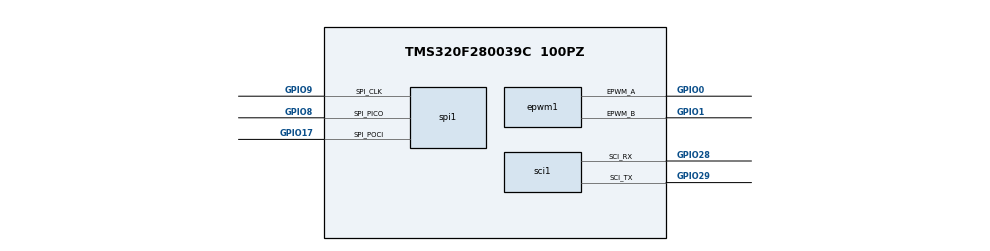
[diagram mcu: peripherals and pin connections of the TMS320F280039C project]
/**
 * These arguments were used when this file was generated. They will be automatically applied on subsequent loads
 * via the GUI or CLI. Run CLI with '--help' for additional information on how to override these arguments.
 * @cliArgs --device "F28003x" --part "F28003x_100PZ" --package "100PZ" --context "system" --product "gmp_pro@1.00.00.05" --product "gmp_pro@1.00.00.05" --product "C2000WARE@5.03.00.00"
 * @v2CliArgs --device "TMS320F280039C" --package "100PZ" --context "system" --product "gmp_pro@1.00.00.05" --product "gmp_pro@1.00.00.05" --product "C2000WARE@5.03.00.00"
 * @versions {"tool":"1.21.0+3721"}
 */

/**
 * Import the modules used in this configuration.
 */
const adc            = scripting.addModule("/driverlib/adc.js", {}, false);
const adc1           = adc.addInstance();
const device_support = scripting.addModule("/driverlib/device_support.js");
const epwm           = scripting.addModule("/driverlib/epwm.js", {}, false);
const epwm1          = epwm.addInstance();
const epwm2          = epwm.addInstance();
const epwm3          = epwm.addInstance();
const sci            = scripting.addModule("/driverlib/sci.js", {}, false);
const sci1           = sci.addInstance();
const spi            = scripting.addModule("/driverlib/spi.js", {}, false);
const spi1           = spi.addInstance();

/**
 * Write custom configuration values to the imported modules.
 */
adc1.$name                          = "myADC0";
adc1.adcClockPrescaler              = "ADC_CLK_DIV_2_0";
adc1.enabledInts                    = ["ADC_INT_NUMBER1"];
adc1.enableInterrupt1ContinuousMode = true;
adc1.enableInterrupt1               = true;

const analog  = scripting.addModule("/driverlib/analog.js", {}, false);
const analog1 = analog.addInstance({}, false);
analog1.$name = "myANALOGPinMux0";
adc1.analog   = analog1;

const divider5       = system.clockTree["PLL_REFDIV"];
divider5.divideValue = 2;

const mux3       = system.clockTree["OSCCLKSRCSEL"];
mux3.inputSelect = "X1_XTAL";

epwm1.$name                                                      = "EPWMU";
epwm1.epwmTimebase_hsClockDiv                                    = "EPWM_HSCLOCK_DIVIDER_1";
epwm1.epwmTimebase_period                                        = 6000;
epwm1.epwmTimebase_counterMode                                   = "EPWM_COUNTER_MODE_UP_DOWN";
epwm1.epwmTimebase_counterModeAfterSync                          = "EPWM_COUNT_MODE_UP_AFTER_SYNC";
epwm1.epwmTimebase_phaseEnable                                   = true;
epwm1.epwmTimebase_syncOutPulseMode                              = ["EPWM_SYNC_OUT_PULSE_ON_CNTR_ZERO"];
epwm1.epwmCounterCompare_cmpA                                    = 3000;
epwm1.epwmCounterCompare_shadowLoadModeCMPA                      = "EPWM_COMP_LOAD_ON_CNTR_ZERO_PERIOD";
epwm1.epwmActionQualifier_EPWM_AQ_OUTPUT_A_ON_TIMEBASE_UP_CMPA   = "EPWM_AQ_OUTPUT_LOW";
epwm1.epwmActionQualifier_EPWM_AQ_OUTPUT_A_ON_TIMEBASE_DOWN_CMPA = "EPWM_AQ_OUTPUT_HIGH";
epwm1.epwmDeadband_delayRED                                      = 75;
epwm1.epwmDeadband_delayFED                                      = 75;
epwm1.epwmEventTrigger_enableInterrupt                           = true;
epwm1.epwmEventTrigger_EPWM_SOC_A_triggerEnable                  = true;
epwm1.epwmEventTrigger_EPWM_SOC_A_triggerSource                  = "EPWM_SOC_TBCTR_PERIOD";
epwm1.epwmEventTrigger_EPWM_SOC_A_triggerEventPrescalar          = "1";
epwm1.epwm.$assign                                               = "EPWM1";
epwm1.epwm.epwm_aPin.$assign                                     = "GPIO0";
epwm1.epwm.epwm_bPin.$assign                                     = "GPIO1";

epwm2.$name = "EPWMV";

epwm3.$name = "EPWMW";

sci1.$name                 = "debug_uart";
sci1.useInterrupts         = false;
sci1.sci.sci_rxPin.$assign = "GPIO28";
sci1.sci.sci_txPin.$assign = "GPIO29";
sci1.rxQual.$name          = "myGPIOQUAL0";
sci1.txQual.$name          = "myGPIOQUAL1";

spi1.$name                   = "Encoder_SPI";
spi1.useCase                 = "CUSTOM";
spi1.useInterfacePins        = ["SPI@_CLK","SPI@_SIMO","SPI@_SOMI"];
spi1.useInterrupts           = false;
spi1.picoQual.$name          = "myGPIOQUAL2";
spi1.pociQual.$name          = "myGPIOQUAL3";
spi1.spi.spi_picoPin.$assign = "GPIO8";
spi1.spi.spi_pociPin.$assign = "GPIO17";
spi1.spi.spi_clkPin.$assign  = "GPIO9";
spi1.clkQual.$name           = "myGPIOQUAL4";

/**
 * Pinmux solution for unlocked pins/peripherals. This ensures that minor changes to the automatic solver in a future
 * version of the tool will not impact the pinmux you originally saw.  These lines can be completely deleted in order to
 * re-solve from scratch.
 */
analog1.analog.$suggestSolution                           = "ANALOG";
analog1.analog["a0/b15/c15/daca_outPin"].$suggestSolution = "A0/B15/C15/DACA_OUT";
analog1.analog["a1/b7/dacb_outPin"].$suggestSolution      = "A1/B7/DACB_OUT";
analog1.analog["a10/b1/c10Pin"].$suggestSolution          = "A10/B1/C10";
analog1.analog["a11/b10/c0Pin"].$suggestSolution          = "A11/B10/C0";
analog1.analog["a12, c5Pin"].$suggestSolution             = "A12, C5";
analog1.analog["a14/b14/c4Pin"].$suggestSolution          = "A14/B14/C4";
analog1.analog["a2/b6/c9Pin"].$suggestSolution            = "A2/B6/C9";
analog1.analog["a3, c7/b9Pin"].$suggestSolution           = "A3, C7/B9";
analog1.analog["a4/b8Pin"].$suggestSolution               = "A4/B8";
analog1.analog.a5Pin.$suggestSolution                     = "A5";
analog1.analog.a6Pin.$suggestSolution                     = "A6";
analog1.analog.a8Pin.$suggestSolution                     = "A8";
analog1.analog.a9Pin.$suggestSolution                     = "A9";
analog1.analog["b0/c11Pin"].$suggestSolution              = "B0/C11";
analog1.analog.b11Pin.$suggestSolution                    = "B11";
analog1.analog["b11, gpio21Pin"].$suggestSolution         = "B11, GPIO21";
analog1.analog["b2/c6Pin"].$suggestSolution               = "B2/C6";
analog1.analog["b3/vdacPin"].$suggestSolution             = "B3/VDAC";
analog1.analog["b4/c8Pin"].$suggestSolution               = "B4/C8";
analog1.analog.b5Pin.$suggestSolution                     = "B5";
analog1.analog["b5, gpio20Pin"].$suggestSolution          = "B5, GPIO20";
analog1.analog.c1Pin.$suggestSolution                     = "C1";
analog1.analog.c14Pin.$suggestSolution                    = "C14";
analog1.analog["c2/b12Pin"].$suggestSolution              = "C2/B12";
analog1.analog["c3/a7Pin"].$suggestSolution               = "C3/A7";
epwm2.epwm.$suggestSolution                               = "EPWM3";
epwm2.epwm.epwm_aPin.$suggestSolution                     = "GPIO14";
epwm2.epwm.epwm_bPin.$suggestSolution                     = "GPIO15";
epwm3.epwm.$suggestSolution                               = "EPWM2";
epwm3.epwm.epwm_aPin.$suggestSolution                     = "GPIO2";
epwm3.epwm.epwm_bPin.$suggestSolution                     = "GPIO3";
sci1.sci.$suggestSolution                                 = "SCIA";
spi1.spi.$suggestSolution                                 = "SPIA";
